# RN831X_RN861X_MCU register map
File version: v0.0.1
CPU: RN831X_RN861X_MCU r1p0, little endian, MPU, no FPU
Registers are 32-bit, read-write, reset 0x0 unless marked. A register's access mark holds for its fields unless they carry their own. Offsets are from the block's base; [hi:lo] are bit positions; {n}, {i} and the like mark numbered series; 'fields as' and 'values as' point back to an identical list.

## ECLIC — Ehanced Core Local Interrupt Controller
Base 0xE0020000
0x00 CFG access not given — A global configuration register.
  [4:1] CFG
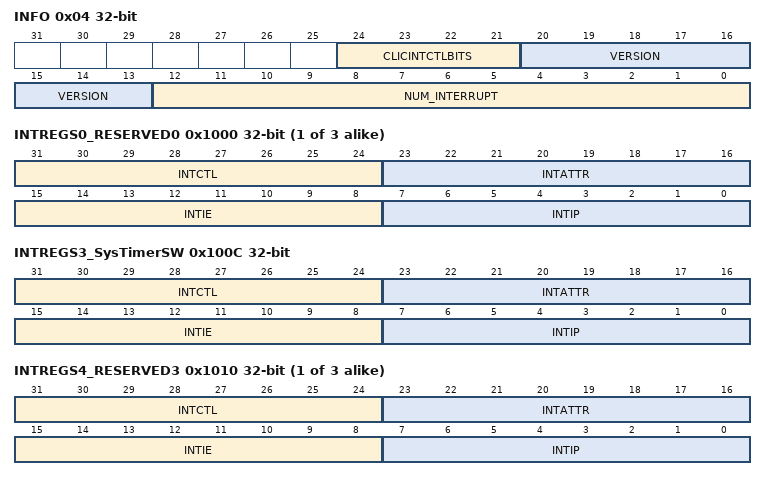
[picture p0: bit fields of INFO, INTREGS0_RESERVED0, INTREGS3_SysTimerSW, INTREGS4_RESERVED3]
0x04 INFO ro — A global info register.
  [24:21] CLICINTCTLBITS — Used to specify the effective bit-width the register clicintctl[i].
  [20:13] VERSION — Hardware implementation version number.
  [12:0] NUM_INTERRUPT — Number of interrupt sources supported by the hardware.
0x08 MTH access not given — Set the target interrupt threshold level.
  [7:0] MTH
{0x1000+4i} INTREGS{i}_RESERVED{i} (i=0..2) — Register pair: intip & intie & intattr & intctl.
  [31:24] INTCTL — The control register of the interrupt source.
  [23:16] INTATTR — Indicate the attribute of the interrupt source.
  [15:8] INTIE — The enable bit register for the interrupt source.
  [7:0] INTIP — The pending flag register for the interrupt source.
0x100C INTREGS3_SysTimerSW — Register pair: intip & intie & intattr & intctl.
  fields as INTREGS0_RESERVED0
{0x1000+4i} INTREGS{i}_RESERVED{i-1} (i=4..6) — Register pair: intip & intie & intattr & intctl.
  fields as INTREGS0_RESERVED0
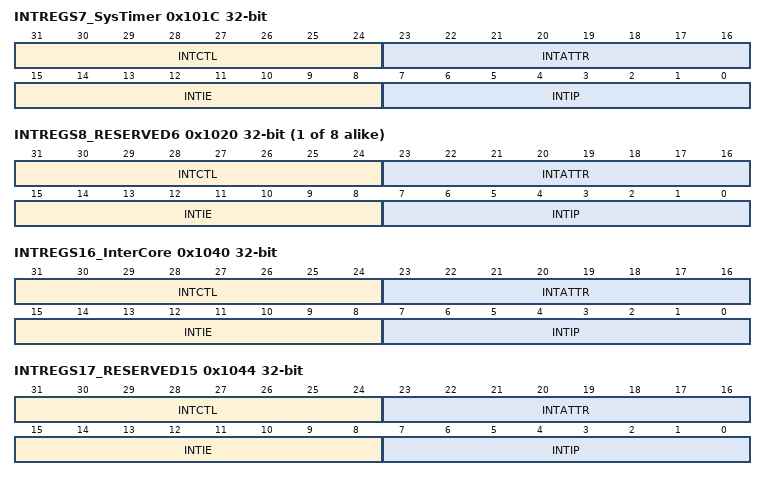
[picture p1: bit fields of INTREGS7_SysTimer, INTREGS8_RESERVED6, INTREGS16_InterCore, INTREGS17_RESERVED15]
0x101C INTREGS7_SysTimer — Register pair: intip & intie & intattr & intctl.
  fields as INTREGS0_RESERVED0
{0x1000+4i} INTREGS{i}_RESERVED{i-2} (i=8..15) — Register pair: intip & intie & intattr & intctl.
  fields as INTREGS0_RESERVED0
0x1040 INTREGS16_InterCore — Register pair: intip & intie & intattr & intctl.
  fields as INTREGS0_RESERVED0
0x1044 INTREGS17_RESERVED15 — Register pair: intip & intie & intattr & intctl.
  fields as INTREGS0_RESERVED0
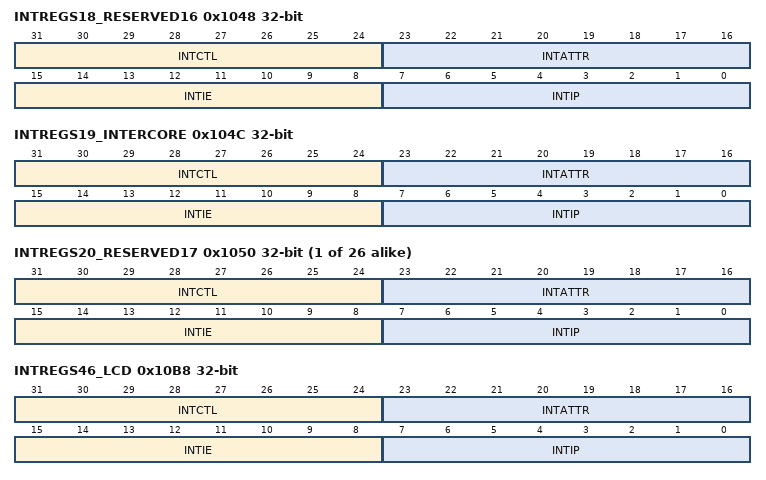
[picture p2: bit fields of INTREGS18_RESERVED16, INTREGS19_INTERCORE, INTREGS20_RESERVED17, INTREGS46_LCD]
0x1048 INTREGS18_RESERVED16 — Register pair: intip & intie & intattr & intctl.
  fields as INTREGS0_RESERVED0
0x104C INTREGS19_INTERCORE — Register pair: intip & intie & intattr & intctl.
  fields as INTREGS0_RESERVED0
{0x1000+4i} INTREGS{i}_RESERVED{i-3} (i=20..45) — Register pair: intip & intie & intattr & intctl.
  fields as INTREGS0_RESERVED0
0x10B8 INTREGS46_LCD — Register pair: intip & intie & intattr & intctl.
  fields as INTREGS0_RESERVED0
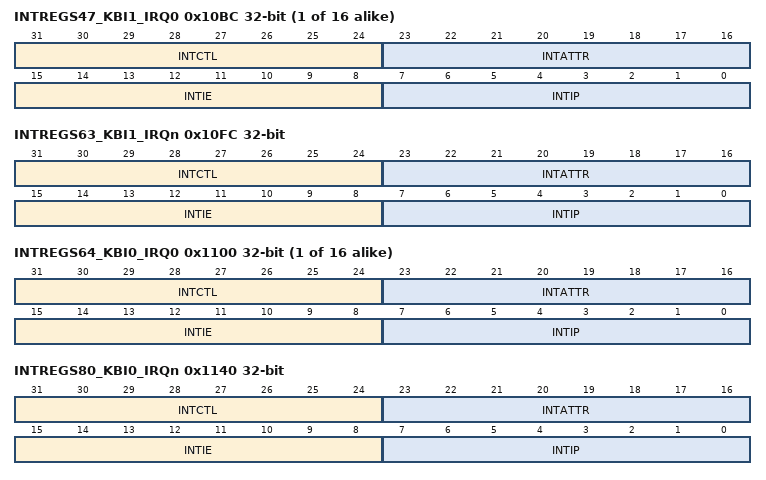
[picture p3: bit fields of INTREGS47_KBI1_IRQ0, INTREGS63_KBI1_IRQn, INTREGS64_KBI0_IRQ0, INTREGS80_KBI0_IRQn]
{0x1000+4i} INTREGS{i}_KBI1_IRQ{i-47} (i=47..62) — Register pair: intip & intie & intattr & intctl.
  fields as INTREGS0_RESERVED0
0x10FC INTREGS63_KBI1_IRQn — Register pair: intip & intie & intattr & intctl.
  fields as INTREGS0_RESERVED0
{0x1000+4i} INTREGS{i}_KBI0_IRQ{i-64} (i=64..79) — Register pair: intip & intie & intattr & intctl.
  fields as INTREGS0_RESERVED0
0x1140 INTREGS80_KBI0_IRQn — Register pair: intip & intie & intattr & intctl.
  fields as INTREGS0_RESERVED0
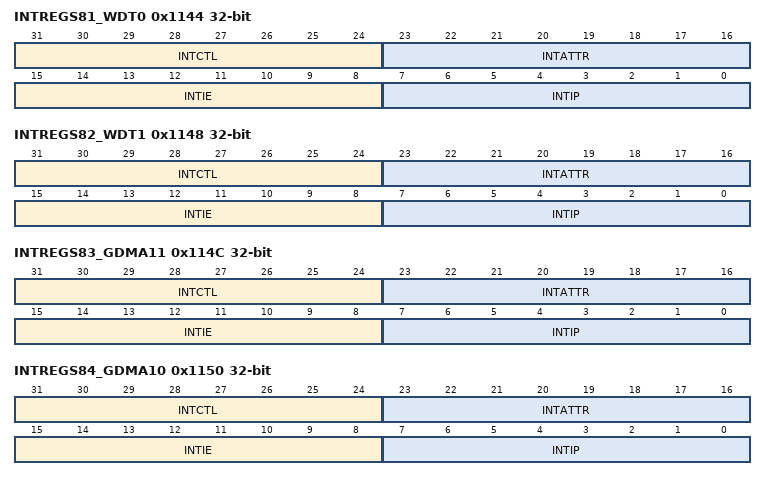
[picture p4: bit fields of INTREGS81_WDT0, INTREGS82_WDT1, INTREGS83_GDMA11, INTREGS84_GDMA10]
0x1144 INTREGS81_WDT0 — Register pair: intip & intie & intattr & intctl.
  fields as INTREGS0_RESERVED0
0x1148 INTREGS82_WDT1 — Register pair: intip & intie & intattr & intctl.
  fields as INTREGS0_RESERVED0
0x114C INTREGS83_GDMA11 — Register pair: intip & intie & intattr & intctl.
  fields as INTREGS0_RESERVED0
0x1150 INTREGS84_GDMA10 — Register pair: intip & intie & intattr & intctl.
  fields as INTREGS0_RESERVED0
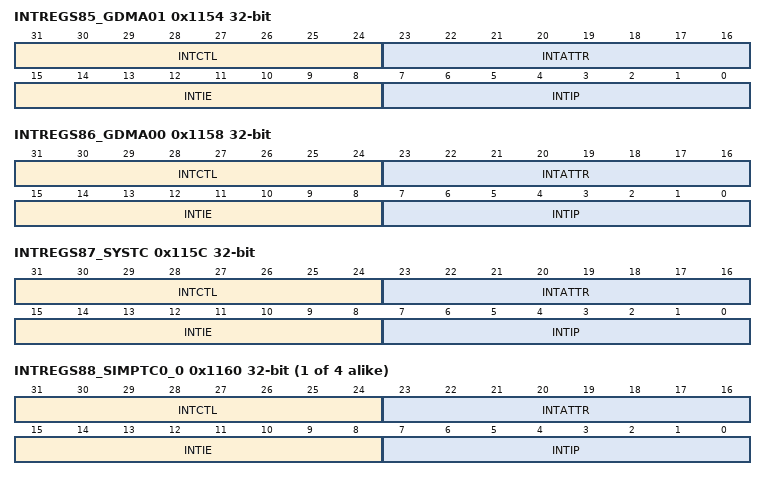
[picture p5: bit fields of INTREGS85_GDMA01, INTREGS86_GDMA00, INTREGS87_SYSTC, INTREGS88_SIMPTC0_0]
0x1154 INTREGS85_GDMA01 — Register pair: intip & intie & intattr & intctl.
  fields as INTREGS0_RESERVED0
0x1158 INTREGS86_GDMA00 — Register pair: intip & intie & intattr & intctl.
  fields as INTREGS0_RESERVED0
0x115C INTREGS87_SYSTC — Register pair: intip & intie & intattr & intctl.
  fields as INTREGS0_RESERVED0
{0x1000+4i} INTREGS{i}_SIMPTC0_{i-88} (i=88..91) — Register pair: intip & intie & intattr & intctl.
  fields as INTREGS0_RESERVED0
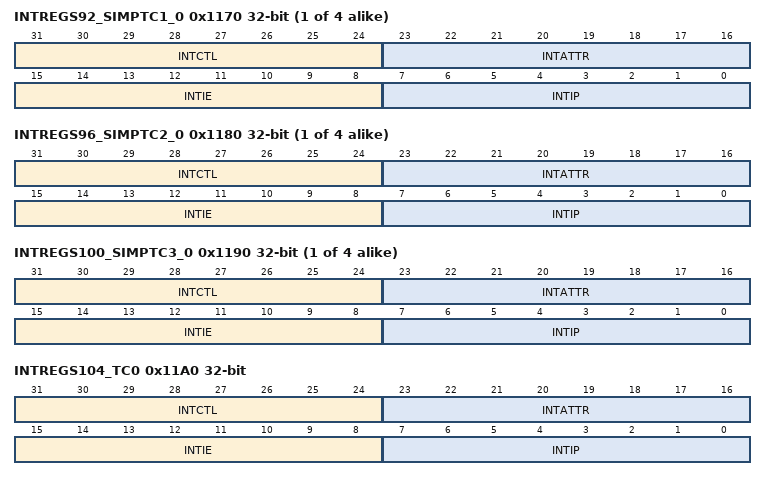
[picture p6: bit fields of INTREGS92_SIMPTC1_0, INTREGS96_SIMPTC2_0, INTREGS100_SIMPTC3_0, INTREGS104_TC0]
{0x1000+4i} INTREGS{i}_SIMPTC1_{i-92} (i=92..95) — Register pair: intip & intie & intattr & intctl.
  fields as INTREGS0_RESERVED0
{0x1000+4i} INTREGS{i}_SIMPTC2_{i-96} (i=96..99) — Register pair: intip & intie & intattr & intctl.
  fields as INTREGS0_RESERVED0
{0x1000+4i} INTREGS{i}_SIMPTC3_{i-100} (i=100..103) — Register pair: intip & intie & intattr & intctl.
  fields as INTREGS0_RESERVED0
0x11A0 INTREGS104_TC0 — Register pair: intip & intie & intattr & intctl.
  fields as INTREGS0_RESERVED0
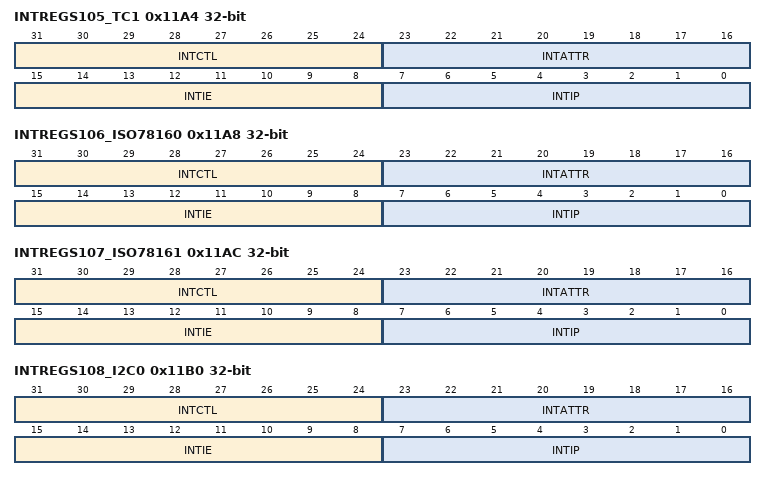
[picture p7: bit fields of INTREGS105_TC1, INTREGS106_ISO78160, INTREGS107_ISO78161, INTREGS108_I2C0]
0x11A4 INTREGS105_TC1 — Register pair: intip & intie & intattr & intctl.
  fields as INTREGS0_RESERVED0
0x11A8 INTREGS106_ISO78160 — Register pair: intip & intie & intattr & intctl.
  fields as INTREGS0_RESERVED0
0x11AC INTREGS107_ISO78161 — Register pair: intip & intie & intattr & intctl.
  fields as INTREGS0_RESERVED0
0x11B0 INTREGS108_I2C0 — Register pair: intip & intie & intattr & intctl.
  fields as INTREGS0_RESERVED0
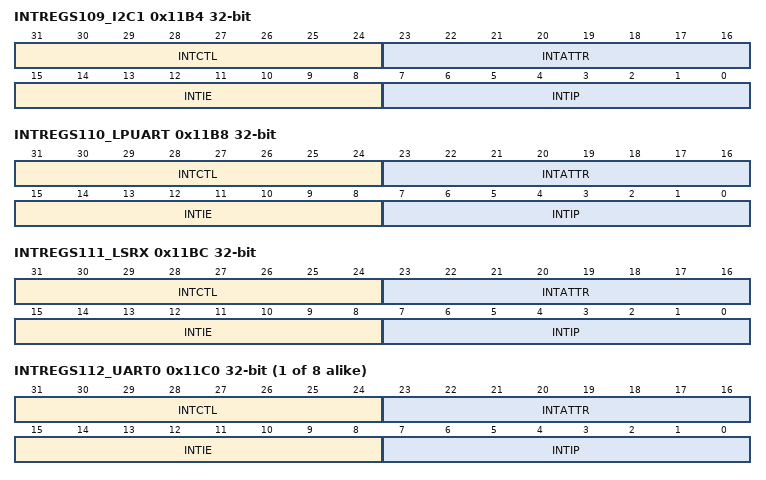
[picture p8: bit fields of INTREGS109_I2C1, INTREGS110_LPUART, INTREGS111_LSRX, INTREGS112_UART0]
0x11B4 INTREGS109_I2C1 — Register pair: intip & intie & intattr & intctl.
  fields as INTREGS0_RESERVED0
0x11B8 INTREGS110_LPUART — Register pair: intip & intie & intattr & intctl.
  fields as INTREGS0_RESERVED0
0x11BC INTREGS111_LSRX — Register pair: intip & intie & intattr & intctl.
  fields as INTREGS0_RESERVED0
{0x1000+4i} INTREGS{i}_UART{i-112} (i=112..119) — Register pair: intip & intie & intattr & intctl.
  fields as INTREGS0_RESERVED0
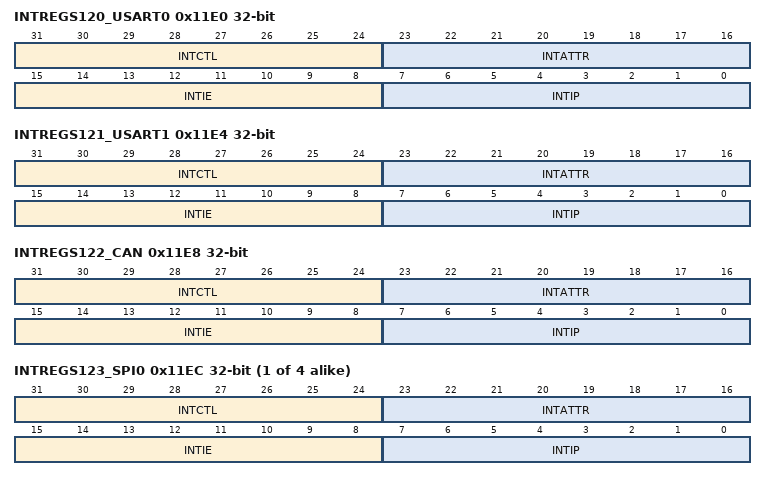
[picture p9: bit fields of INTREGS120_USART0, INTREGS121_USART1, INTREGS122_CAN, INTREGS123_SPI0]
0x11E0 INTREGS120_USART0 — Register pair: intip & intie & intattr & intctl.
  fields as INTREGS0_RESERVED0
0x11E4 INTREGS121_USART1 — Register pair: intip & intie & intattr & intctl.
  fields as INTREGS0_RESERVED0
0x11E8 INTREGS122_CAN — Register pair: intip & intie & intattr & intctl.
  fields as INTREGS0_RESERVED0
{0x1000+4i} INTREGS{i}_SPI{i-123} (i=123..126) — Register pair: intip & intie & intattr & intctl.
  fields as INTREGS0_RESERVED0
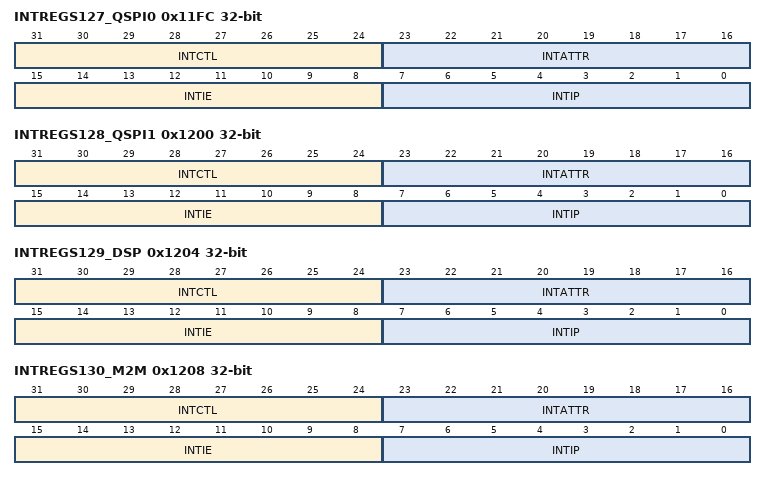
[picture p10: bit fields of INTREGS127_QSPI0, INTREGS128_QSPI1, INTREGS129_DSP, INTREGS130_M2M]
0x11FC INTREGS127_QSPI0 — Register pair: intip & intie & intattr & intctl.
  fields as INTREGS0_RESERVED0
0x1200 INTREGS128_QSPI1 — Register pair: intip & intie & intattr & intctl.
  fields as INTREGS0_RESERVED0
0x1204 INTREGS129_DSP — Register pair: intip & intie & intattr & intctl.
  fields as INTREGS0_RESERVED0
0x1208 INTREGS130_M2M — Register pair: intip & intie & intattr & intctl.
  fields as INTREGS0_RESERVED0
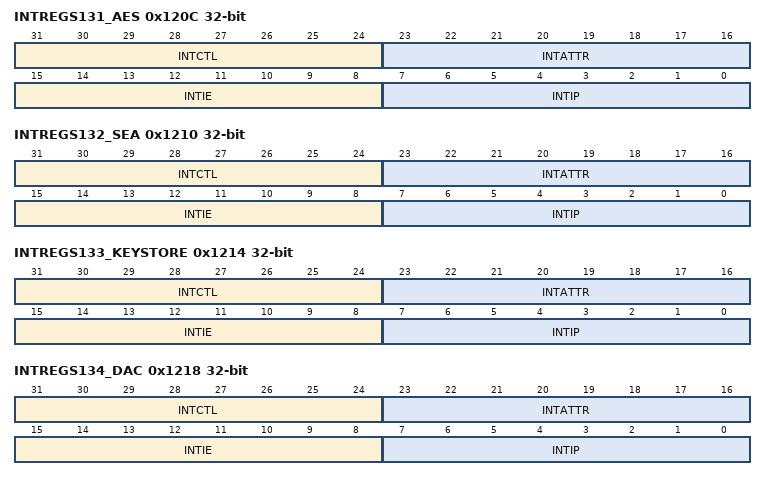
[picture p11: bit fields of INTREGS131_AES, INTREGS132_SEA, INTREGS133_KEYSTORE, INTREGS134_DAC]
0x120C INTREGS131_AES — Register pair: intip & intie & intattr & intctl.
  fields as INTREGS0_RESERVED0
0x1210 INTREGS132_SEA — Register pair: intip & intie & intattr & intctl.
  fields as INTREGS0_RESERVED0
0x1214 INTREGS133_KEYSTORE — Register pair: intip & intie & intattr & intctl.
  fields as INTREGS0_RESERVED0
0x1218 INTREGS134_DAC — Register pair: intip & intie & intattr & intctl.
  fields as INTREGS0_RESERVED0
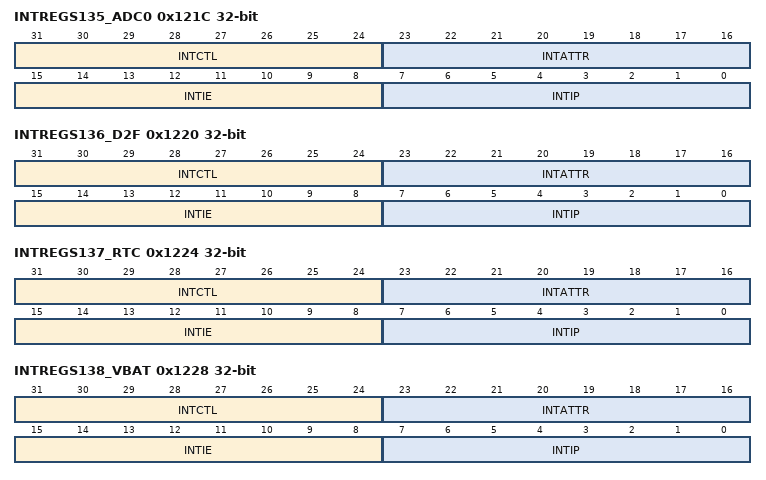
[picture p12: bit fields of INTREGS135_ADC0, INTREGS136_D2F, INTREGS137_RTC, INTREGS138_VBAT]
0x121C INTREGS135_ADC0 — Register pair: intip & intie & intattr & intctl.
  fields as INTREGS0_RESERVED0
0x1220 INTREGS136_D2F — Register pair: intip & intie & intattr & intctl.
  fields as INTREGS0_RESERVED0
0x1224 INTREGS137_RTC — Register pair: intip & intie & intattr & intctl.
  fields as INTREGS0_RESERVED0
0x1228 INTREGS138_VBAT — Register pair: intip & intie & intattr & intctl.
  fields as INTREGS0_RESERVED0
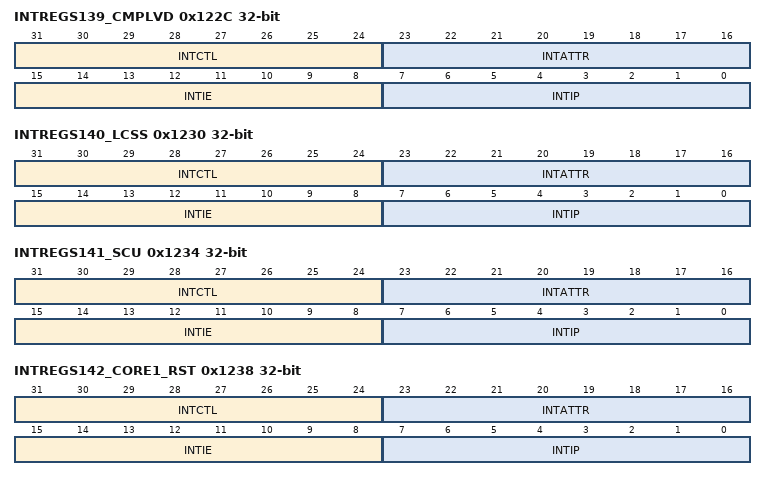
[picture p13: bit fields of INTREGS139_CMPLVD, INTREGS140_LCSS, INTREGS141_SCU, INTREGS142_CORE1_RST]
0x122C INTREGS139_CMPLVD — Register pair: intip & intie & intattr & intctl.
  fields as INTREGS0_RESERVED0
0x1230 INTREGS140_LCSS — Register pair: intip & intie & intattr & intctl.
  fields as INTREGS0_RESERVED0
0x1234 INTREGS141_SCU — Register pair: intip & intie & intattr & intctl.
  fields as INTREGS0_RESERVED0
0x1238 INTREGS142_CORE1_RST — Register pair: intip & intie & intattr & intctl.
  fields as INTREGS0_RESERVED0
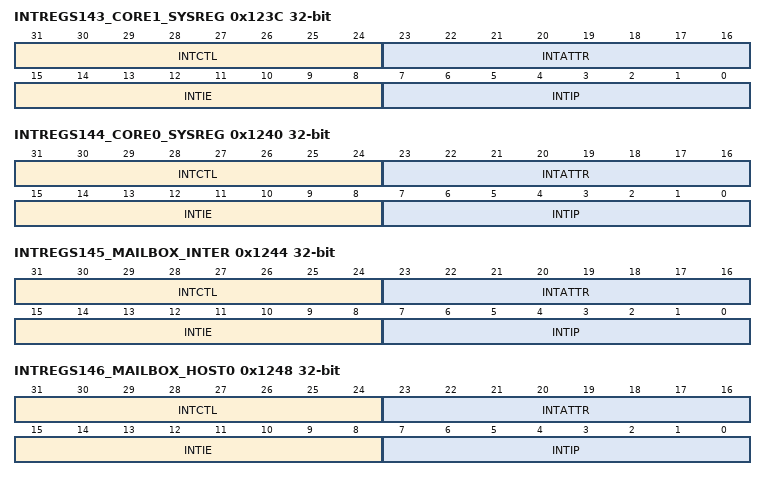
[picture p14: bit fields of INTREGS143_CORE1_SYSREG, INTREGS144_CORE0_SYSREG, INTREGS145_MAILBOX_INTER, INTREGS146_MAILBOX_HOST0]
0x123C INTREGS143_CORE1_SYSREG — Register pair: intip & intie & intattr & intctl.
  fields as INTREGS0_RESERVED0
0x1240 INTREGS144_CORE0_SYSREG — Register pair: intip & intie & intattr & intctl.
  fields as INTREGS0_RESERVED0
0x1244 INTREGS145_MAILBOX_INTER — Register pair: intip & intie & intattr & intctl.
  fields as INTREGS0_RESERVED0
0x1248 INTREGS146_MAILBOX_HOST0 — Register pair: intip & intie & intattr & intctl.
  fields as INTREGS0_RESERVED0
